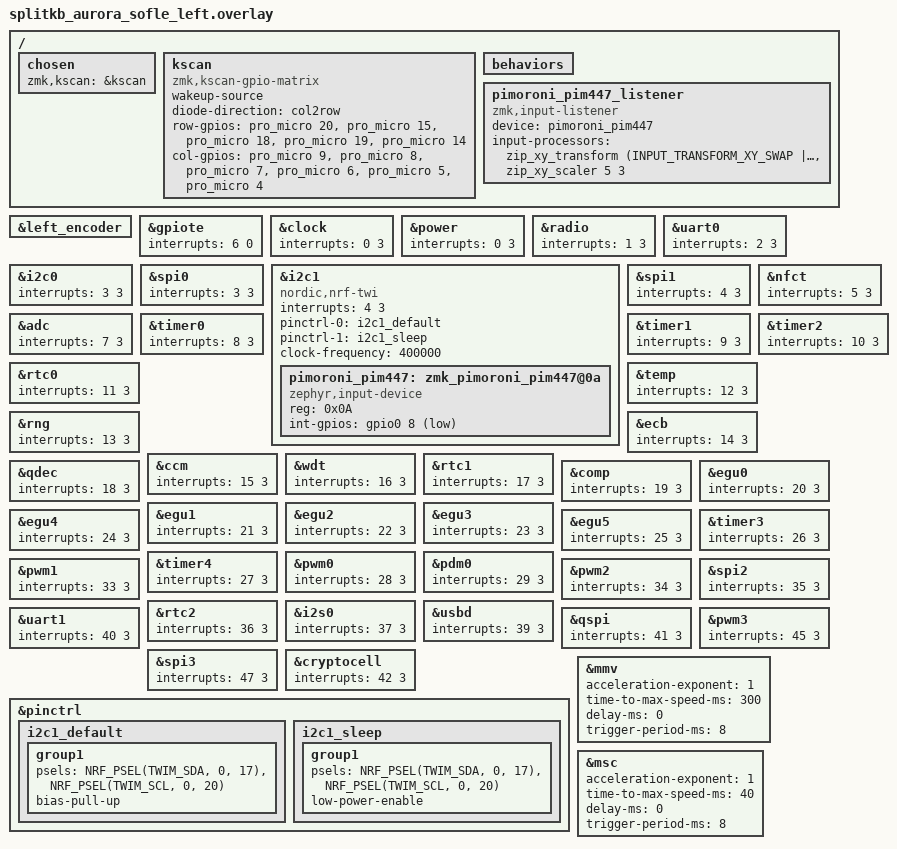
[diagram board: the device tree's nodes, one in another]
/*
 * Copyright (c) 2023 The ZMK Contributors
 *
 * SPDX-License-Identifier: MIT
 */

#include "splitkb_aurora_sofle.dtsi"

/ {
    chosen {
        zmk,kscan = &kscan;
    };

    kscan: kscan {
        compatible = "zmk,kscan-gpio-matrix";
        wakeup-source;

        diode-direction = "col2row";

        row-gpios
            = <&pro_micro 20 (GPIO_PULL_DOWN | GPIO_ACTIVE_HIGH)>
            , <&pro_micro 15 (GPIO_PULL_DOWN | GPIO_ACTIVE_HIGH)>
            , <&pro_micro 18 (GPIO_PULL_DOWN | GPIO_ACTIVE_HIGH)>
            , <&pro_micro 19 (GPIO_PULL_DOWN | GPIO_ACTIVE_HIGH)>
            , <&pro_micro 14 (GPIO_PULL_DOWN | GPIO_ACTIVE_HIGH)>
            ;

        col-gpios
            = <&pro_micro 9 GPIO_ACTIVE_HIGH>
            , <&pro_micro 8 GPIO_ACTIVE_HIGH>
            , <&pro_micro 7 GPIO_ACTIVE_HIGH>
            , <&pro_micro 6 GPIO_ACTIVE_HIGH>
            , <&pro_micro 5 GPIO_ACTIVE_HIGH>
            , <&pro_micro 4 GPIO_ACTIVE_HIGH>
            ;
    };
};

&left_encoder {
    status = "okay";
};

// Adjust GPIO interrupt priority to the highest level.
//
// IMPORTANT TLDR:
// If you are using the nice_nano_v2 board, you don't need to make changes to
// the config below and can leave it as it is.
//
// Explanation of these settings:
//
// PS/2 events must be processed within 30-50us, but frequently bluetooth and
// other interrupts take longer to finish.
//
// Therefore we change the default GPIO priority to the highest level (0) and
// demote all BT interrupt priorities by one level using the kconfig settings:
// - CONFIG_BT_CTLR_LLL_PRIO 1
// - CONFIG_BT_CTLR_ULL_HIGH_PRIO 2
// - CONFIG_BT_CTLR_ULL_LOW_PRIOCONFIG 2
//
// These config options are enabled automatically by the PS2 UART and GPIO
// drivers... so you don't have to enable them manually.
//
// Then we lower the interrupt priority of all other devices by 2 levels using
// the devicetree config below.
//
// This allows the PS/2 interrupts to be triggered faster and reduces
// transmission errors.
//
// If you are using the nice_nano_v2 board, you can reuse my config below.
//
// Otherwise, you can generate the interrupt overrides using this script:
// https://github.com/infused-kim/kb_zmk_ps2_mouse_trackpoint_driver/blob/main/scripts/gen_interrupt_priority_overrides.py
//
// Make sure to do it on a zephyr.dts where the interrupts have not been
// adjusted yet (i.e. a config that doesn't have the the following options
// enabled).
//
// If you are building using a toolchain you can find the zephyr.dts in the
// build directory, which by default is: `app/build/zephyr/zephyr.dts`
//
// If you are building using the github actions, copy the output of the build
// step `xxxx_right - nice_nano_v2 Devicetree file` into a file and run the
// script on it.

// gpiote should have the highest interrupt priority (0)
&gpiote {
    interrupts = < 6 0 >;
};

// All other priorities should be two levels lower than their defaults
// (which is usually 1 and should be demoted to 3)
&clock {
    interrupts = < 0 3 >;
};

&power {
    interrupts = < 0 3 >;
};

&radio {
    interrupts = < 1 3 >;
};

&uart0 {
    interrupts = < 2 3 >;
};

&i2c0 {
    interrupts = < 3 3 >;
};

&spi0 {
    interrupts = < 3 3 >;
};

&i2c1 {
    interrupts = < 4 3 >;
};

&spi1 {
    interrupts = < 4 3 >;
};

&nfct {
    interrupts = < 5 3 >;
};

&adc {
    interrupts = < 7 3 >;
};

&timer0 {
    interrupts = < 8 3 >;
};

&timer1 {
    interrupts = < 9 3 >;
};

&timer2 {
    interrupts = < 10 3 >;
};

&rtc0 {
    interrupts = < 11 3 >;
};

&temp {
    interrupts = < 12 3 >;
};

&rng {
    interrupts = < 13 3 >;
};

&ecb {
    interrupts = < 14 3 >;
};

&ccm {
    interrupts = < 15 3 >;
};

&wdt {
    interrupts = < 16 3 >;
};

&rtc1 {
    interrupts = < 17 3 >;
};

&qdec {
    interrupts = < 18 3 >;
};

&comp {
    interrupts = < 19 3 >;
};

&egu0 {
    interrupts = < 20 3 >;
};

&egu1 {
    interrupts = < 21 3 >;
};

&egu2 {
    interrupts = < 22 3 >;
};

&egu3 {
    interrupts = < 23 3 >;
};

&egu4 {
    interrupts = < 24 3 >;
};

&egu5 {
    interrupts = < 25 3 >;
};

&timer3 {
    interrupts = < 26 3 >;
};

&timer4 {
    interrupts = < 27 3 >;
};

&pwm0 {
    interrupts = < 28 3 >;
};

&pdm0 {
    interrupts = < 29 3 >;
};

&pwm1 {
    interrupts = < 33 3 >;
};

&pwm2 {
    interrupts = < 34 3 >;
};

&spi2 {
    interrupts = < 35 3 >;
};

&rtc2 {
    interrupts = < 36 3 >;
};

&i2s0 {
    interrupts = < 37 3 >;
};

&usbd {
    interrupts = < 39 3 >;
};

&uart1 {
    interrupts = < 40 3 >;
};

&qspi {
    interrupts = < 41 3 >;
};

&pwm3 {
    interrupts = < 45 3 >;
};

&spi3 {
    interrupts = < 47 3 >;
};

&cryptocell {
    interrupts = < 42 3 >;
};


// trackball stuff added below

#define ZMK_MOUSE_DEFAULT_MOVE_VAL 600  // 600
#define ZMK_MOUSE_DEFAULT_SCRL_VAL 10    // 10

#include <dt-bindings/zmk/mouse.h>

#include <behaviors/mouse_keys.dtsi>
#include <behaviors/mouse_move.dtsi>

#include <input/processors.dtsi>
#include <dt-bindings/zmk/input_transform.h>

&pinctrl {
    i2c1_default: i2c1_default {
        group1 {
            psels = <NRF_PSEL(TWIM_SDA, 0, 17)>,
                    <NRF_PSEL(TWIM_SCL, 0, 20)>;
            bias-pull-up;
        };
    };

    i2c1_sleep: i2c1_sleep {
        group1 {
            psels = <NRF_PSEL(TWIM_SDA, 0, 17)>,
                    <NRF_PSEL(TWIM_SCL, 0, 20)>;
            low-power-enable;
        };
    };
};

&i2c1 {
    status = "okay";

    compatible = "nordic,nrf-twi";
    pinctrl-0 = <&i2c1_default>;
    pinctrl-1 = <&i2c1_sleep>;
    pinctrl-names = "default", "sleep";
    clock-frequency = <400000>;

    pimoroni_pim447: zmk_pimoroni_pim447@0a {
        compatible = "zephyr,input-device", "zmk,pimoroni-pim447";
        reg = <0x0A>;
		int-gpios = <&gpio0 8 (GPIO_ACTIVE_LOW | GPIO_PULL_UP)>;
        // automouse-layer = <3>;
    };
};

&mmv {
    acceleration-exponent = <1>;  // 1
    time-to-max-speed-ms = <300>; // 300
    delay-ms = <0>;
    trigger-period-ms = <8>;      // 16
};

&msc {
    acceleration-exponent = <1>;  // 0
    time-to-max-speed-ms = <40>;  // 300
    delay-ms = <0>;
    trigger-period-ms = <8>;      // 16
};

/ {
    behaviors {
        // mmv: mouse_move {
        //     compatible = "zmk,behavior-input-two-axis";
        //     #binding-cells = <1>;
        //     x-input-code = <INPUT_REL_X>;
        //     y-input-code = <INPUT_REL_Y>;
        //     time-to-max-speed-ms = <500>;
        //     acceleration-exponent = <1>;
        // };
    };

	pimoroni_pim447_listener {
		compatible = "zmk,input-listener";
		device = <&pimoroni_pim447>;
        input-processors = <&zip_xy_transform (INPUT_TRANSFORM_XY_SWAP | INPUT_TRANSFORM_X_INVERT)>, <&zip_xy_scaler 5 3>;
	};
};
